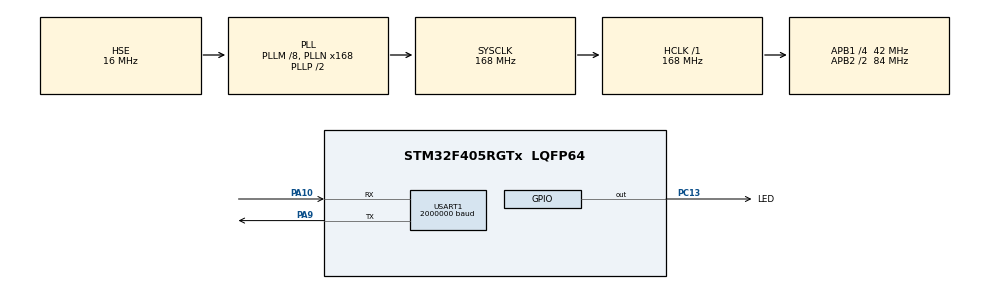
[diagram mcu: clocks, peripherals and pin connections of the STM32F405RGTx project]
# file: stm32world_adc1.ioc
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ADC1.Channel-0\#ChannelRegularConversion=ADC_CHANNEL_TEMPSENSOR
ADC1.Channel-1\#ChannelRegularConversion=ADC_CHANNEL_VREFINT
ADC1.Channel-2\#ChannelRegularConversion=ADC_CHANNEL_VBAT
ADC1.DMAContinuousRequests=ENABLE
ADC1.ExternalTrigConv=ADC_EXTERNALTRIGCONV_T8_TRGO
ADC1.NbrOfConversion=3
ADC1.NbrOfConversionFlag=1
ADC1.Rank-0\#ChannelRegularConversion=1
ADC1.Rank-1\#ChannelRegularConversion=2
ADC1.Rank-2\#ChannelRegularConversion=3
ADC1.SamplingTime-0\#ChannelRegularConversion=ADC_SAMPLETIME_84CYCLES
ADC1.SamplingTime-1\#ChannelRegularConversion=ADC_SAMPLETIME_84CYCLES
ADC1.SamplingTime-2\#ChannelRegularConversion=ADC_SAMPLETIME_84CYCLES
ADC1.master=1
Dma.ADC1.0.Direction=DMA_PERIPH_TO_MEMORY
Dma.ADC1.0.FIFOMode=DMA_FIFOMODE_DISABLE
Dma.ADC1.0.Instance=DMA2_Stream0
Dma.ADC1.0.MemDataAlignment=DMA_MDATAALIGN_HALFWORD
Dma.ADC1.0.MemInc=DMA_MINC_ENABLE
Dma.ADC1.0.Mode=DMA_CIRCULAR
Dma.ADC1.0.PeriphDataAlignment=DMA_PDATAALIGN_HALFWORD
Dma.ADC1.0.PeriphInc=DMA_PINC_DISABLE
Dma.ADC1.0.Priority=DMA_PRIORITY_LOW
Dma.Request0=ADC1
Mcu.Family=STM32F4
Mcu.Name=STM32F405RGTx
Mcu.Package=LQFP64
NVIC.DMA2_Stream0_IRQn=true\:0\:0\:false\:false\:true\:false\:true\:true
NVIC.PriorityGroup=NVIC_PRIORITYGROUP_4
PA10.Mode=Asynchronous
PA10.Signal=USART1_RX
PA13.Mode=Trace_Asynchronous_SW
PA13.Signal=SYS_JTMS-SWDIO
PA14.Mode=Trace_Asynchronous_SW
PA14.Signal=SYS_JTCK-SWCLK
PA9.Mode=Asynchronous
PA9.Signal=USART1_TX
PB3.Mode=Trace_Asynchronous_SW
PB3.Signal=SYS_JTDO-SWO
PC13-ANTI_TAMP.GPIO_Label=LED
PC13-ANTI_TAMP.GPIO_ModeDefaultOutputPP=GPIO_MODE_OUTPUT_OD
PC13-ANTI_TAMP.GPIO_PuPd=GPIO_NOPULL
PC13-ANTI_TAMP.PinState=GPIO_PIN_SET
PC13-ANTI_TAMP.Signal=GPIO_Output
PH0-OSC_IN.Mode=HSE-External-Oscillator
PH0-OSC_IN.Signal=RCC_OSC_IN
PH1-OSC_OUT.Mode=HSE-External-Oscillator
PH1-OSC_OUT.Signal=RCC_OSC_OUT
ProjectManager.HeapSize=0x200
ProjectManager.StackSize=0x400
ProjectManager.TargetToolchain=STM32CubeIDE
RCC.48MHZClocksFreq_Value=84000000
RCC.AHBFreq_Value=168000000
RCC.APB1CLKDivider=RCC_HCLK_DIV4
RCC.APB1Freq_Value=42000000
RCC.APB1TimFreq_Value=84000000
RCC.APB2CLKDivider=RCC_HCLK_DIV2
RCC.APB2Freq_Value=84000000
RCC.APB2TimFreq_Value=168000000
RCC.CortexFreq_Value=168000000
RCC.HCLKFreq_Value=168000000
RCC.HSE_VALUE=16000000
RCC.HSI_VALUE=16000000
RCC.LSE_VALUE=32768
RCC.PLLM=8
RCC.PLLN=168
RCC.PLLSourceVirtual=RCC_PLLSOURCE_HSE
RCC.SYSCLKFreq_VALUE=168000000
RCC.SYSCLKSource=RCC_SYSCLKSOURCE_PLLCLK
RCC.VCOOutputFreq_Value=336000000
TIM8.AutoReloadPreload=TIM_AUTORELOAD_PRELOAD_ENABLE
TIM8.Period=1000 - 1
TIM8.Prescaler=168 - 1
TIM8.TIM_MasterOutputTrigger=TIM_TRGO_UPDATE
USART1.BaudRate=2000000
USART1.OverSampling=UART_OVERSAMPLING_8
USART1.VirtualMode=VM_ASYNC
VP_ADC1_TempSens_Input.Mode=IN-TempSens
VP_ADC1_Vbat_Input.Mode=IN-Vbat
VP_ADC1_Vref_Input.Mode=IN-Vrefint
VP_TIM8_VS_ClockSourceINT.Mode=Internal
board=custom

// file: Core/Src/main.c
/* USER CODE BEGIN Header */
/**
 ******************************************************************************
 * @file           : main.c
 * @brief          : Main program body
 ******************************************************************************
 * @attention
 *
 * Copyright (c) 2025 Lars Boegild Thomsen <lth@stm32world.com>
 * All rights reserved.
 *
 * This software is licensed under terms that can be found in the LICENSE file
 * in the root directory of this software component.
 * If no LICENSE file comes with this software, it is provided AS-IS.
 *
 ******************************************************************************
 */
/* USER CODE END Header */
#include "main.h"

/* USER CODE BEGIN Includes */
#include <stdio.h>
#include <math.h>
/* USER CODE END Includes */

/* USER CODE BEGIN PD */

#define ADC_RESOLUTION 4096
#define DMA_SAMPLES 10
#define DMA_BUFFER_SIZE 3 * DMA_SAMPLES

/* USER CODE END PD */

ADC_HandleTypeDef hadc1;
DMA_HandleTypeDef hdma_adc1;

TIM_HandleTypeDef htim8;

UART_HandleTypeDef huart1;

/* USER CODE BEGIN PV */
uint16_t dma_buffer[2 * DMA_BUFFER_SIZE];

uint16_t temp_avg, vref_avg, vbat_avg;

uint32_t cb;

double vdda = 0.0;
double temp = 0.0;
double vref = 0.0;
/* USER CODE END PV */

void SystemClock_Config(void);
static void MX_GPIO_Init(void);
static void MX_DMA_Init(void);
static void MX_USART1_UART_Init(void);
static void MX_ADC1_Init(void);
static void MX_TIM8_Init(void);

/* USER CODE BEGIN 0 */

// Send printf to uart1
int _write(int fd, char *ptr, int len) {
    HAL_StatusTypeDef hstatus;

    if (fd == 1 || fd == 2) {
        hstatus = HAL_UART_Transmit(&huart1, (uint8_t*) ptr, len, HAL_MAX_DELAY);
        if (hstatus == HAL_OK)
            return len;
        else
            return -1;
    }
    return -1;
}

void process_buffer(uint16_t *buffer) {

    uint32_t temp_sum = 0, vref_sum = 0, vbat_sum = 0;

    //if (cb % 50 == 0) HAL_GPIO_TogglePin(LED_GPIO_Port, LED_Pin);

    for (int i = 0; i < DMA_SAMPLES; ++i) {
        temp_sum += buffer[0];
        vref_sum += buffer[1];
        vbat_sum += buffer[2];
        buffer += 3;
    }

    temp_avg = temp_sum / DMA_SAMPLES;
    vref_avg = vref_sum / DMA_SAMPLES;
    vbat_avg = vbat_sum / DMA_SAMPLES;

    // VDDA can be calculated based on the measured vref and the calibration data
    vdda = (float) VREFINT_CAL_VREF * (float) *VREFINT_CAL_ADDR / vref_avg / 1000;

    // Knowing vdda and the resolution of adc - the actual voltage can be calculated
    vref = (float) vdda / ADC_RESOLUTION * vref_avg;

    // Temperature can be calculated based on the
    temp = (float) ((float) ((float) (TEMPSENSOR_CAL2_TEMP - TEMPSENSOR_CAL1_TEMP) / (float) (*TEMPSENSOR_CAL2_ADDR - *TEMPSENSOR_CAL1_ADDR)) * (temp_avg - *TEMPSENSOR_CAL1_ADDR) + TEMPSENSOR_CAL1_TEMP);

    ++cb;
}

void HAL_ADC_ConvHalfCpltCallback(ADC_HandleTypeDef *hadc) {
    process_buffer(&dma_buffer[0]);
}

void HAL_ADC_ConvCpltCallback(ADC_HandleTypeDef *hadc) {
    process_buffer(&dma_buffer[DMA_BUFFER_SIZE]);
}

/* USER CODE END 0 */

int main(void)
{

  /* MCU Configuration--------------------------------------------------------*/

  /* Reset of all peripherals, Initializes the Flash interface and the Systick. */
  HAL_Init();

  /* Configure the system clock */
  SystemClock_Config();

  /* Initialize all configured peripherals */
  MX_GPIO_Init();
  MX_DMA_Init();
  MX_USART1_UART_Init();
  MX_ADC1_Init();
  MX_TIM8_Init();
  /* USER CODE BEGIN 2 */

    printf("\n\n\n------------\nADC Starting\n");

    HAL_TIM_Base_Start_IT(&htim8);

    HAL_ADC_Start_DMA(&hadc1, (uint32_t*) &dma_buffer, 2 * DMA_BUFFER_SIZE);

  /* USER CODE END 2 */

  /* Infinite loop */
  /* USER CODE BEGIN WHILE */

    uint32_t loop_cnt = 0, now = 0, next_tick = 1000;

    while (1) {

        now = uwTick;

        if (now >= next_tick) {
            //printf("Tick %lu (loop %lu)\n", now / 1000, loop_cnt);
            printf("Tick %lu (loop=%lu cb=%lu) vdda=%0.3f vref=%0.3f temp=%0.2f\n", now / 1000, loop_cnt, cb, vdda, vref, temp);
            loop_cnt = 0;
            next_tick = now + 1000;
        }

        ++loop_cnt;

    /* USER CODE END WHILE */

    }
}

void SystemClock_Config(void)
{
  RCC_OscInitTypeDef RCC_OscInitStruct = {0};
  RCC_ClkInitTypeDef RCC_ClkInitStruct = {0};

  /** Configure the main internal regulator output voltage
  */
  __HAL_RCC_PWR_CLK_ENABLE();
  __HAL_PWR_VOLTAGESCALING_CONFIG(PWR_REGULATOR_VOLTAGE_SCALE1);

  /** Initializes the RCC Oscillators according to the specified parameters
  * in the RCC_OscInitTypeDef structure.
  */
  RCC_OscInitStruct.OscillatorType = RCC_OSCILLATORTYPE_HSE;
  RCC_OscInitStruct.HSEState = RCC_HSE_ON;
  RCC_OscInitStruct.PLL.PLLState = RCC_PLL_ON;
  RCC_OscInitStruct.PLL.PLLSource = RCC_PLLSOURCE_HSE;
  RCC_OscInitStruct.PLL.PLLM = 8;
  RCC_OscInitStruct.PLL.PLLN = 168;
  RCC_OscInitStruct.PLL.PLLP = RCC_PLLP_DIV2;
  RCC_OscInitStruct.PLL.PLLQ = 4;
  if (HAL_RCC_OscConfig(&RCC_OscInitStruct) != HAL_OK)
  {
    Error_Handler();
  }

  /** Initializes the CPU, AHB and APB buses clocks
  */
  RCC_ClkInitStruct.ClockType = RCC_CLOCKTYPE_HCLK|RCC_CLOCKTYPE_SYSCLK
                              |RCC_CLOCKTYPE_PCLK1|RCC_CLOCKTYPE_PCLK2;
  RCC_ClkInitStruct.SYSCLKSource = RCC_SYSCLKSOURCE_PLLCLK;
  RCC_ClkInitStruct.AHBCLKDivider = RCC_SYSCLK_DIV1;
  RCC_ClkInitStruct.APB1CLKDivider = RCC_HCLK_DIV4;
  RCC_ClkInitStruct.APB2CLKDivider = RCC_HCLK_DIV2;

  if (HAL_RCC_ClockConfig(&RCC_ClkInitStruct, FLASH_LATENCY_5) != HAL_OK)
  {
    Error_Handler();
  }
}

static void MX_ADC1_Init(void)
{

  ADC_ChannelConfTypeDef sConfig = {0};

  /** Configure the global features of the ADC (Clock, Resolution, Data Alignment and number of conversion)
  */
  hadc1.Instance = ADC1;
  hadc1.Init.ClockPrescaler = ADC_CLOCK_SYNC_PCLK_DIV4;
  hadc1.Init.Resolution = ADC_RESOLUTION_12B;
  hadc1.Init.ScanConvMode = ENABLE;
  hadc1.Init.ContinuousConvMode = DISABLE;
  hadc1.Init.DiscontinuousConvMode = DISABLE;
  hadc1.Init.ExternalTrigConvEdge = ADC_EXTERNALTRIGCONVEDGE_RISING;
  hadc1.Init.ExternalTrigConv = ADC_EXTERNALTRIGCONV_T8_TRGO;
  hadc1.Init.DataAlign = ADC_DATAALIGN_RIGHT;
  hadc1.Init.NbrOfConversion = 3;
  hadc1.Init.DMAContinuousRequests = ENABLE;
  hadc1.Init.EOCSelection = ADC_EOC_SINGLE_CONV;
  if (HAL_ADC_Init(&hadc1) != HAL_OK)
  {
    Error_Handler();
  }

  /** Configure for the selected ADC regular channel its corresponding rank in the sequencer and its sample time.
  */
  sConfig.Channel = ADC_CHANNEL_TEMPSENSOR;
  sConfig.Rank = 1;
  sConfig.SamplingTime = ADC_SAMPLETIME_84CYCLES;
  if (HAL_ADC_ConfigChannel(&hadc1, &sConfig) != HAL_OK)
  {
    Error_Handler();
  }

  /** Configure for the selected ADC regular channel its corresponding rank in the sequencer and its sample time.
  */
  sConfig.Channel = ADC_CHANNEL_VREFINT;
  sConfig.Rank = 2;
  if (HAL_ADC_ConfigChannel(&hadc1, &sConfig) != HAL_OK)
  {
    Error_Handler();
  }

  /** Configure for the selected ADC regular channel its corresponding rank in the sequencer and its sample time.
  */
  sConfig.Channel = ADC_CHANNEL_VBAT;
  sConfig.Rank = 3;
  if (HAL_ADC_ConfigChannel(&hadc1, &sConfig) != HAL_OK)
  {
    Error_Handler();
  }

}

static void MX_TIM8_Init(void)
{

  TIM_ClockConfigTypeDef sClockSourceConfig = {0};
  TIM_MasterConfigTypeDef sMasterConfig = {0};

  htim8.Instance = TIM8;
  htim8.Init.Prescaler = 168 - 1;
  htim8.Init.CounterMode = TIM_COUNTERMODE_UP;
  htim8.Init.Period = 1000 - 1;
  htim8.Init.ClockDivision = TIM_CLOCKDIVISION_DIV1;
  htim8.Init.RepetitionCounter = 0;
  htim8.Init.AutoReloadPreload = TIM_AUTORELOAD_PRELOAD_ENABLE;
  if (HAL_TIM_Base_Init(&htim8) != HAL_OK)
  {
    Error_Handler();
  }
  sClockSourceConfig.ClockSource = TIM_CLOCKSOURCE_INTERNAL;
  if (HAL_TIM_ConfigClockSource(&htim8, &sClockSourceConfig) != HAL_OK)
  {
    Error_Handler();
  }
  sMasterConfig.MasterOutputTrigger = TIM_TRGO_UPDATE;
  sMasterConfig.MasterSlaveMode = TIM_MASTERSLAVEMODE_DISABLE;
  if (HAL_TIMEx_MasterConfigSynchronization(&htim8, &sMasterConfig) != HAL_OK)
  {
    Error_Handler();
  }

}

static void MX_USART1_UART_Init(void)
{

  huart1.Instance = USART1;
  huart1.Init.BaudRate = 2000000;
  huart1.Init.WordLength = UART_WORDLENGTH_8B;
  huart1.Init.StopBits = UART_STOPBITS_1;
  huart1.Init.Parity = UART_PARITY_NONE;
  huart1.Init.Mode = UART_MODE_TX_RX;
  huart1.Init.HwFlowCtl = UART_HWCONTROL_NONE;
  huart1.Init.OverSampling = UART_OVERSAMPLING_8;
  if (HAL_UART_Init(&huart1) != HAL_OK)
  {
    Error_Handler();
  }

}

static void MX_DMA_Init(void)
{

  /* DMA controller clock enable */
  __HAL_RCC_DMA2_CLK_ENABLE();

  /* DMA interrupt init */
  /* DMA2_Stream0_IRQn interrupt configuration */
  HAL_NVIC_SetPriority(DMA2_Stream0_IRQn, 0, 0);
  HAL_NVIC_EnableIRQ(DMA2_Stream0_IRQn);

}

static void MX_GPIO_Init(void)
{
  GPIO_InitTypeDef GPIO_InitStruct = {0};

  /* GPIO Ports Clock Enable */
  __HAL_RCC_GPIOC_CLK_ENABLE();
  __HAL_RCC_GPIOH_CLK_ENABLE();
  __HAL_RCC_GPIOA_CLK_ENABLE();
  __HAL_RCC_GPIOB_CLK_ENABLE();

  /*Configure GPIO pin Output Level */
  HAL_GPIO_WritePin(LED_GPIO_Port, LED_Pin, GPIO_PIN_SET);

  /*Configure GPIO pin : LED_Pin */
  GPIO_InitStruct.Pin = LED_Pin;
  GPIO_InitStruct.Mode = GPIO_MODE_OUTPUT_OD;
  GPIO_InitStruct.Pull = GPIO_NOPULL;
  GPIO_InitStruct.Speed = GPIO_SPEED_FREQ_LOW;
  HAL_GPIO_Init(LED_GPIO_Port, &GPIO_InitStruct);

}

void Error_Handler(void)
{
    __disable_irq();
    while (1)
    {
    }
}
